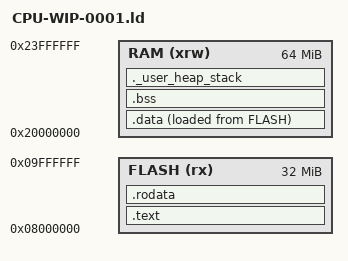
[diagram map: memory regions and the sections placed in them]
/*
* Modified from ARM machines
*/

/* Entry Point */
ENTRY(main)

/* Highest address of the user mode stack */
_estack = ORIGIN(RAM) + LENGTH(RAM); /* end of "RAM" Ram type memory */

_Min_Heap_Size = 0xA00000 ; /* required amount of heap */
_Min_Stack_Size = 0x800000 ; /* required amount of stack */

/* Memories definition */
MEMORY
{
  RAM    (xrw)    : ORIGIN = 0x20000000,   LENGTH = 64M
  FLASH    (rx)   : ORIGIN = 0x08000000,   LENGTH = 32M
}

/* Sections */
SECTIONS
{

  /* The program code and other data into "FLASH" Rom type memory */
  .text :
  {
    . = ALIGN(8);
    *(.text)           /* .text sections (code) */
    *(.text*)          /* .text* sections (code) */
    *(.eh_frame)

    . = ALIGN(8);
    _etext = .;        /* define a global symbols at end of code */
  } >FLASH

  /* Constant data into "FLASH" Rom type memory */
  .rodata :
  {
    . = ALIGN(8);
    *(.rodata)         /* .rodata sections (constants, strings, etc.) */
    *(.rodata*)        /* .rodata* sections (constants, strings, etc.) */
    *(.srodata.cst16) *(.srodata.cst8) *(.srodata.cst4) *(.srodata.cst2)
    *(.srodata .srodata.*) *(.sdata .sdata.* .gnu.linkonce.s.*)
    . = ALIGN(8);
  } >FLASH

  /* Initialized data sections into "RAM" Ram type memory */
  .data :
  {
    . = ALIGN(8);
    _sdata = .;        /* create a global symbol at data start */
    *(.data)           /* .data sections */
    *(.data*)          /* .data* sections */

    . = ALIGN(8);
    _edata = .;        /* define a global symbol at data end */

  } >RAM AT> FLASH

  /* Uninitialized data section into "RAM" Ram type memory */
  . = ALIGN(8);
  .bss :
  {
    /* This is used by the startup in order to initialize the .bss section */
    _sbss = .;         /* define a global symbol at bss start */
    __bss_start__ = _sbss;
    *(.bss)
    *(.bss*)
    *(COMMON)

    . = ALIGN(8);
    _ebss = .;         /* define a global symbol at bss end */
    __bss_end__ = _ebss;
  } >RAM

  /* User_heap_stack section, used to check that there is enough "RAM" Ram  type memory left */
  ._user_heap_stack :
  {
    . = ALIGN(8);
    PROVIDE ( end = . );
    PROVIDE ( _end = . );
    . = . + _Min_Heap_Size;
    . = . + _Min_Stack_Size;
    . = ALIGN(8);
  } >RAM

  /* Remove information from the compiler libraries */
  /DISCARD/ :
  {
    libc.a ( * )
    libm.a ( * )
    libgcc.a ( * )
  }
}
